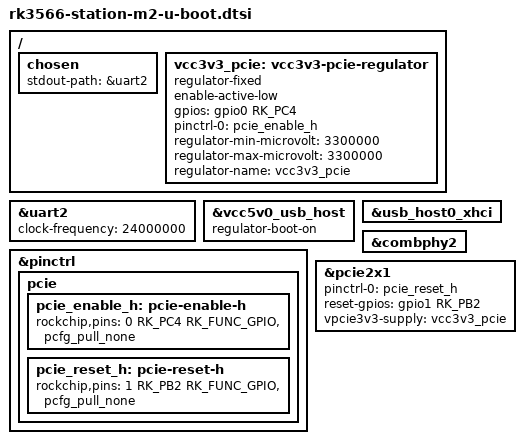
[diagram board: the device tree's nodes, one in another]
// SPDX-License-Identifier: (GPL-2.0+ OR MIT)
/*
 * Copyright (c) 2023 Arm
 */

#include "rk356x-u-boot.dtsi"

/ {
	chosen {
		stdout-path = &uart2;
	};

	vcc3v3_pcie: vcc3v3-pcie-regulator {
		compatible = "regulator-fixed";
		enable-active-low;
		gpios = <&gpio0 RK_PC4 GPIO_ACTIVE_HIGH>;
		pinctrl-names = "default";
		pinctrl-0 = <&pcie_enable_h>;
		regulator-min-microvolt = <3300000>;
		regulator-max-microvolt = <3300000>;
		regulator-name = "vcc3v3_pcie";
	};
};

&uart2 {
	clock-frequency = <24000000>;
	bootph-all;
	status = "okay";
};

&vcc5v0_usb_host {
	regulator-boot-on;
};

&usb_host0_xhci {
	status = "okay";
};

&combphy2 {
	status = "okay";
};

&pinctrl {
	pcie {
		pcie_enable_h: pcie-enable-h {
			rockchip,pins = <0 RK_PC4 RK_FUNC_GPIO &pcfg_pull_none>;
		};

		pcie_reset_h: pcie-reset-h {
			rockchip,pins = <1 RK_PB2 RK_FUNC_GPIO &pcfg_pull_none>;
		};
	};
};

&pcie2x1 {
	pinctrl-names = "default";
	pinctrl-0 = <&pcie_reset_h>;
	reset-gpios = <&gpio1 RK_PB2 GPIO_ACTIVE_HIGH>;
	vpcie3v3-supply = <&vcc3v3_pcie>;
	status = "okay";
};
